# 3065PNPIRH register map
File version: 1.0
3065PNPIRH registers
Registers are 32-bit, access per field, reset 0x0 unless marked. A register's access mark holds for its fields unless they carry their own. Offsets are from the block's base; lines under a group give offsets from that group; [hi:lo] are bit positions; {n}, {i} and the like mark numbered series; 'fields as' and 'values as' point back to an identical list; <NAME> marks a mode.

## Memory map
0x10000000 CRG size 0xF14 — CRG peripheral interface
0x10010000 CMM size 0x2C — CMM peripheral interface
0x10020000 CFD size 0x20 — CFD peripheral interface
0x10100000 SYSCTRL0 size 0xE88 — SYSCTRL0 peripheral interface
0x10100000 SYSCTRL1 size 0x9004 — SYSCTRL1 peripheral interface
0x14000000 UART0 size 0x64 — UART0 peripheral interface
0x14001000 UART1 size 0x64
0x14002000 UART2 size 0x64
0x14003000 UART3 size 0x64
0x14004000 UART4 size 0x64
0x14100000 I2C0 size 0x110 — I2C0 peripheral interface
0x14101000 I2C1 size 0x110
0x14200000 SPI0 size 0x34 — SPI0 peripheral interface
0x14201000 SPI1 size 0x34
0x14300000 TIMER0 size 0x24 — TIMER0 peripheral interface
0x14301000 TIMER1 size 0x24
0x14302000 TIMER2 size 0x24
0x14303000 TIMER3 size 0x24
0x14400000 WWDG_CFG size 0x20 — WWDG_CFG peripheral interface
0x14401000 IWDG_CFG size 0x24 — IWDG_CFG peripheral interface
0x14500000 GPIO0 size 0x420 — GPIO0 peripheral interface
{0x14500000+0x1000*n} GPIO{n} size 0x420 (n=1..9)
0x14600000 CAN size 0x168 — CAN peripheral interface
0x14700000 GPT0 size 0x508 — GPT0 peripheral interface
0x14701000 GPT1 size 0x508
0x14702000 GPT2 size 0x508
0x14703000 GPT3 size 0x508
0x14710000 FLASH size 0x608 — FLASH peripheral interface
0x14710800 FLASH_EX size 0x330 — FLASH_EX peripheral interface
0x147E0000 PMC size 0xF10 — PMC peripheral interface
0x147F0000 IOCMG_AON size 0x108 — IOCMG_AON peripheral interface
0x147F0000 IOCMG_CORE size 0x124 — IOCMG_CORE peripheral interface
0x14800000 CRC size 0x24 — CRC peripheral interface
0x14A00000 APT0 size 0x808 — APT0 peripheral interface
{0x14A00000+0x1000*n} APT{n} size 0x808 (n=1..8)
0x14B00000 CAPM0 size 0x50 — CAPM0 peripheral interface
0x14B01000 CAPM1 size 0x50
0x14B02000 CAPM2 size 0x50
0x14B03000 CAPM_COMM size 0x34 — CAPM_COMM peripheral interface
0x14C00000 QDM0 size 0x6C — QDM0 peripheral interface
0x14C01000 QDM1 size 0x6C
0x18000000 ADC0 size 0x830 — ADC peripheral interface
0x18001000 ADC1 size 0x830
0x18002000 ADC2 size 0x830
0x18200000 PGA0 size 0x24 — PGA0 peripheral interface
0x18201000 PGA1 size 0x24
0x18202000 PGA2 size 0x24
0x18300000 ACMP0 size 0x90 — ACMP0 peripheral interface
0x18301000 ACMP1 size 0x90
0x18302000 ACMP2 size 0x90
0x18400000 DAC0 size 0x8C — DAC0 peripheral interface
0x18401000 DAC1 size 0x8C
0x18402000 DAC2 size 0x8C
0x18500000 TSENSOR_REG size 0x14 — TSENSOR_REG peripheral interface
0x1C000000 DMA — DMA peripheral interface

## FLASH_EX — FLASH_EX peripheral interface
Base 0x14710800
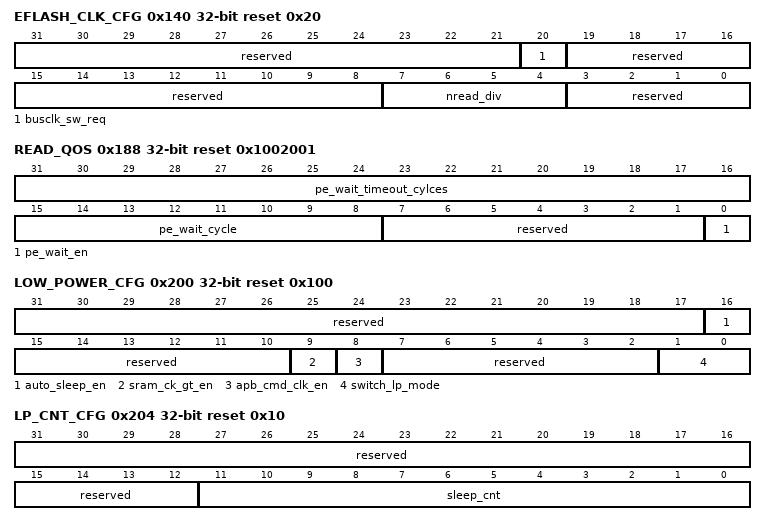
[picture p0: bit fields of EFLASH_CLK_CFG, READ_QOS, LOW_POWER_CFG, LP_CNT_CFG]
0x140 EFLASH_CLK_CFG reset 0x20 — EFLASH_CLK_CFG为时钟分频寄存器。
  [31:21] reserved ro — 保留。
  [20] busclk_sw_req rw — nread_div是否切换完成配置查询寄存器。 写1后触发电路进行切换，回读判断是否切换完成。 读0：切换完成； 读1：切换未完成。
  [19:8] reserved ro — 保留。
  [7:4] nread_div rw — Flash Read，系统总线主时钟与Flash时钟比值（n+1）。 0x0：1分频； 0x1：2分频； …… 0xF：16分频。
  [3:0] reserved ro — 保留。
0x188 READ_QOS reset 0x1002001 — READ_QOS为读QOS配置寄存器。
  [31:16] pe_wait_timeout_cylces rw — pe_wait使能后，PE（Program and Erase）请求被阻塞cycle超过pe_wait_timeout_cylces+pe_wait_cycles，提高PE请求优先级，优先响应PE请求。
  [15:8] pe_wait_cycle rw — 为避免稀疏的Read操作被PE操作阻塞，在完成Read操作后维持pe_wait_cycle个cycle（总线时钟），在此期间阻塞PE请求。 0表示不阻塞。
  [7:1] reserved ro — 保留。
  [0] pe_wait_en rw — PE_wait功能使能。 0：不使能； 1：使能，Read结束后，在pe_wait_cycle时间内，阻塞PE请求，在此cycle内入股有新的Read请求，会优先响应Read。
0x200 LOW_POWER_CFG reset 0x100 — LOW_POWER_CFG为低功耗控制寄存器。
  [31:17] reserved ro — 保留。
  [16] auto_sleep_en rw — 自动休眠低功耗功能控制。 0：关闭； 1：开启，当Main状态机IDLE时间超过sleep_cnt阈值时，逻辑自动控制Macro进入DPD（Deep Power Down）模式。
  [15:10] reserved ro — 保留。
  [9] sram_ck_gt_en rw — 内部SRAM时钟动态门控使能控制。 0：SRAM时钟常开； 1：SRAM时钟动态门控，需要读写时逻辑自动打开，读写结束自动关闭。
  [8] apb_cmd_clk_en rw — Flash CMD相关逻辑时钟使能控制。 0：关闭Erase/Program相关数字逻辑时钟； 1：打开Erase/Program相关数字逻辑时钟。
  [7:2] reserved ro — 保留。
  [1:0] switch_lp_mode rw — 软件直接控制低功耗切换。 00：操作完成； 01：唤醒； 10：睡眠； 11：保留。 软件写入非0值，触发状态跳转，跳转完成寄存器自动回到0。
0x204 LP_CNT_CFG reset 0x10 — LP_CNT_CFG为低功耗计数控制寄存器。
  [31:12] reserved ro — 保留。
  [11:0] sleep_cnt rw — 自动低功耗IDLE等待时间（us时钟计数）。 不可为0，最大2.6ms。 默认：16us。
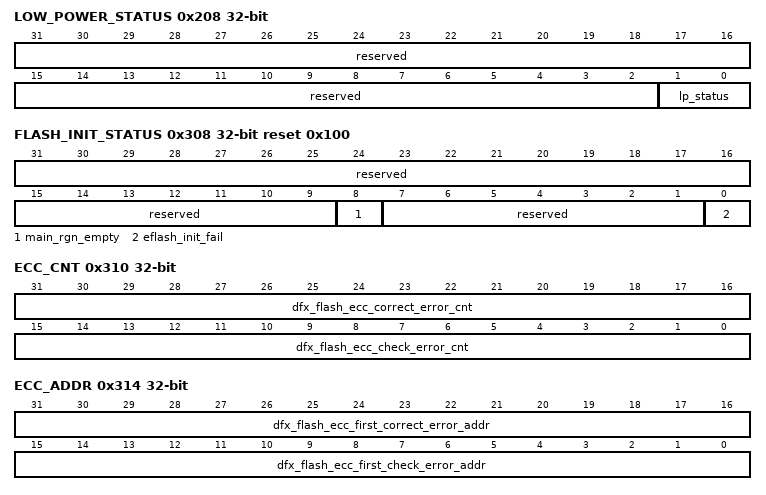
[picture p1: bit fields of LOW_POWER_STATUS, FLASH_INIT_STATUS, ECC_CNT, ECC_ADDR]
0x208 LOW_POWER_STATUS ro — LOW_POWER_STATUS为低功耗状态寄存器。
  [31:2] reserved — 保留。
  [1:0] lp_status — 控制器低功耗状态指示寄存器。 00：正常工作； 01：初始化； 10：睡眠； 11：下电。
0x308 FLASH_INIT_STATUS ro reset 0x100 — FLASH_INIT_STATUS为初始化状态寄存器。
  [31:9] reserved — 保留。
  [8] main_rgn_empty — Main Region第一个地址是否被编程执行寄存器。 0：第一个地址被编程过； 1：第一个地址未被编程过。
  [7:1] reserved — 保留。
  [0] eflash_init_fail — Flash初始化失败标志位。
0x310 ECC_CNT ro — ECC_CNT为ECC错误计数寄存器。
  [31:16] dfx_flash_ecc_correct_error_cnt — Main Region或Information Region读数据发生ECC纠错失败次数，每次对应一个64bit。 软件清除int_raw_err_ecc_corr原始中断后，重新统计。
  [15:0] dfx_flash_ecc_check_error_cnt — Main Region或Information Region读数据发生ECC检查错误次数，每次对应一个64bit。 软件清除int_raw_err_ecc_chk 原始中断后，重新统计。
0x314 ECC_ADDR ro — ECC_ADDR为ECC错误地址寄存器。
  [31:16] dfx_flash_ecc_first_correct_error_addr — 读Flash第一次发生ECC检查错误的物理地址，Unit:64bit。 软件清除int_raw_err_ecc_corr原始中断后，重新统计。 最高2位表示区域： 00：表示Main Region； 01：表示In[A1] [A2] formation Region。
  [15:0] dfx_flash_ecc_first_check_error_addr — 读Flash第一次发生ECC检查错误的物理地址，Unit:64bit。 软件清除int_raw_err_ecc_chk 原始中断后，重新统计。 最高2位表示区域： 00：表示Main Region； 01：表示Informatio[A3] [A4] n Region。
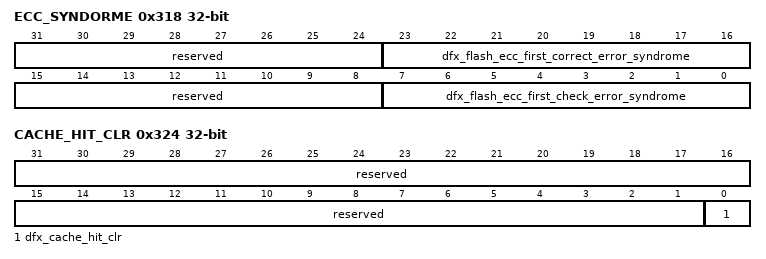
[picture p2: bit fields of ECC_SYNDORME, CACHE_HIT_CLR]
0x318 ECC_SYNDORME ro — ECC_SYNDORME为ECC错误码寄存器。
  [31:24] reserved — 保留。
  [23:16] dfx_flash_ecc_first_correct_error_syndrome — 读Flash第一次发生ECC纠错错误的错误字符。 软件清除int_raw_err_ecc_corr 原始中断后，重新统计。
  [15:8] reserved — 保留。
  [7:0] dfx_flash_ecc_first_check_error_syndrome — 读Flash第一次发生ECC检查错误的错误字符。 软件清除int_raw_err_ecc_chk 原始中断后，重新统计。
0x324 CACHE_HIT_CLR — CACHE_HIT_CLR为Cache命中率清除寄存器。
  [31:1] reserved ro — 保留。
  [0] dfx_cache_hit_clr rw write-1-clears — CACHE_LOOKUP_CNT[dfx_cache_lookup_cnt]与CACHE_HIT_CNT[dfx_cache_hit_cnt计]数器清零控制寄存器。 写0：无效果； 写1：CACHE_LOOKUP_CNT[dfx_cache_lookup_cnt]与CACHE_HIT_CNT[dfx_cache_hit_cnt]清零。
0x328 CACHE_LOOKUP_CNT ro — CACHE_LOOKUP_CNT为Cache查询次数寄存器。
  [31:0] dfx_cache_lookup_cnt — Cache查询次数统计计数器。 Unit：次。
0x32C CACHE_HIT_CNT ro — CACHE_HIT_CNT为Cache命中次数寄存器。
  [31:0] dfx_cache_hit_cnt — cache查询命中次数统计计数器。 Unit：次。
